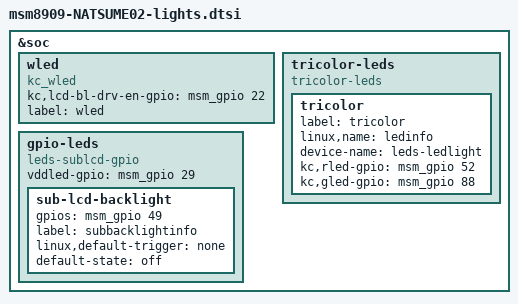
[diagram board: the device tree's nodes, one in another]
/*
 * This software is contributed or developed by KYOCERA Corporation.
 * (C) 2019 KYOCERA Corporation
 *
 * This program is free software; you can redistribute it and/or modify
 * it under the terms of the GNU General Public License version 2 and
 * only version 2 as published by the Free Software Foundation.
 *
 * This program is distributed in the hope that it will be useful,
 * but WITHOUT ANY WARRANTY; without even the implied warranty of
 * MERCHANTABILITY or FITNESS FOR A PARTICULAR PURPOSE.  See the
 * GNU General Public License for more details.
 */

&soc {

	wled {
		compatible = "kc_wled";
		kc,lcd-bl-drv-en-gpio = <&msm_gpio 22 0x00>;
		label = "wled";
	};
	
	tricolor-leds {
		compatible = "tricolor-leds";
		tricolor {
			status = "okay";
			label = "tricolor";
			linux,name = "ledinfo";
			device-name = "leds-ledlight";
			kc,rled-gpio = <&msm_gpio 52 0>;
			kc,gled-gpio = <&msm_gpio 88 0>;
			//use-mdm-led;
		};
	};


	gpio-leds {
		compatible = "leds-sublcd-gpio";
		status = "okay";
		//spamp-gpio = <&msm_gpio 36 0>;
		vddled-gpio = <&msm_gpio 29 0>;

		sub-lcd-backlight {
			gpios = <&msm_gpio 49 0>;
			label = "subbacklightinfo";
			linux,default-trigger = "none";
			default-state = "off";
		};
	};


};
